# Port_7_8_2 register map
Vendor: Texas Instruments
Peripheral module from a debugger description file (folder msp430).
Registers are 8-bit, read-write, reset 0x0 unless marked. A register's access mark holds for its fields unless they carry their own. Offsets are as the file gives them; lines under a group give offsets from that group; [hi:lo] are bit positions; {n}, {i} and the like mark numbered series; 'fields as' and 'values as' point back to an identical list; <NAME> marks a mode.

## Port_7/8
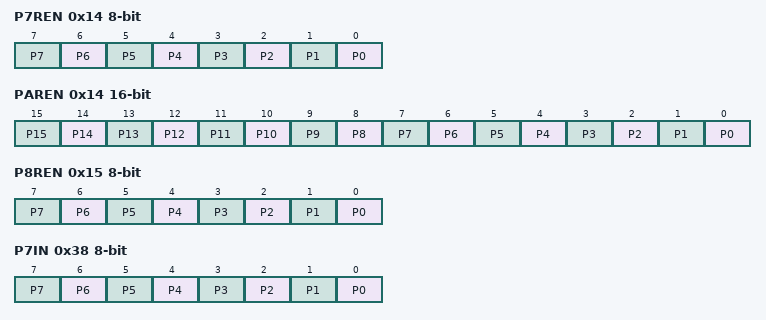
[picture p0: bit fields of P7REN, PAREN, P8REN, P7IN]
0x14 P7REN — Port 7 Resistor Enable
  [n] P{n} (n=0..7)
0x14 PAREN 16-bit — Port A Resistor Enable
  [n] P{n} (n=0..15)
0x15 P8REN — Port 8 Resistor Enable
  [n] P{n} (n=0..7)
0x38 P7IN — Port 7 Input
  [n] P{n} (n=0..7)
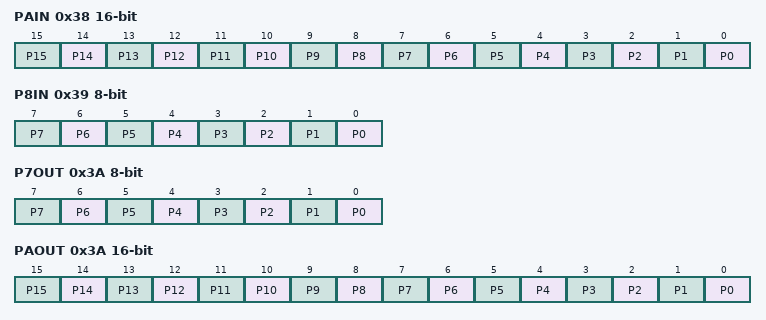
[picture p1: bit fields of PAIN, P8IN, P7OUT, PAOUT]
0x38 PAIN 16-bit — Port A Input
  [n] P{n} (n=0..15)
0x39 P8IN — Port 8 Input
  [n] P{n} (n=0..7)
0x3A P7OUT — Port 7 Output
  [n] P{n} (n=0..7)
0x3A PAOUT 16-bit — Port A Output
  [n] P{n} (n=0..15)
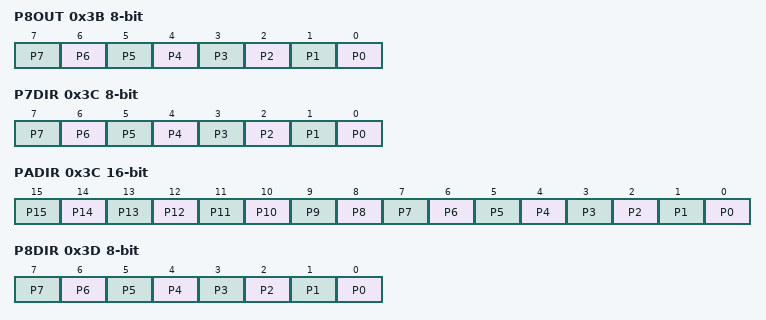
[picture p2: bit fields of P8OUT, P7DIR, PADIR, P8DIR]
0x3B P8OUT — Port 8 Output
  [n] P{n} (n=0..7)
0x3C P7DIR — Port 7 Direction
  [n] P{n} (n=0..7)
0x3C PADIR 16-bit — Port A Direction
  [n] P{n} (n=0..15)
0x3D P8DIR — Port 8 Direction
  [n] P{n} (n=0..7)
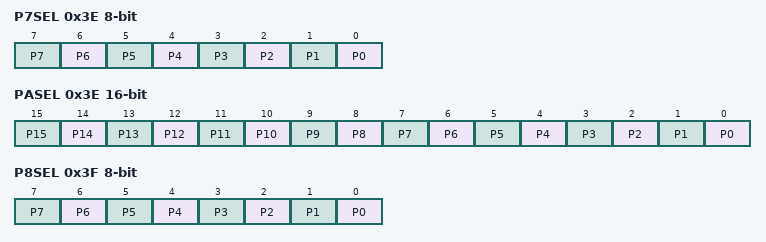
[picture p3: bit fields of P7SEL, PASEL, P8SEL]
0x3E P7SEL — Port 7 Selection
  [n] P{n} (n=0..7)
0x3E PASEL 16-bit — Port A Selection
  [n] P{n} (n=0..15)
0x3F P8SEL — Port 8 Selection
  [n] P{n} (n=0..7)
